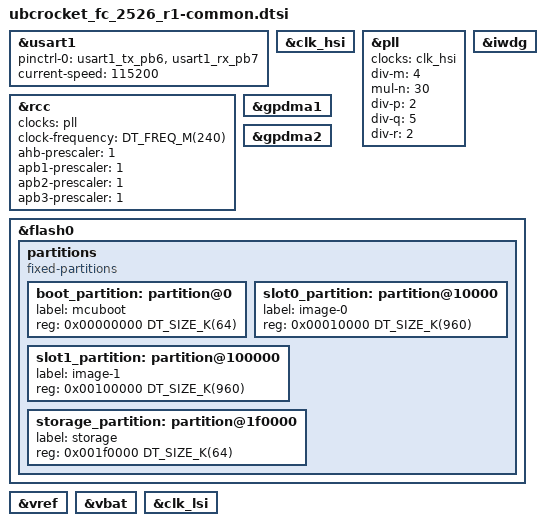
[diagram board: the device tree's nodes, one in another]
/*
 * Copyright (c) 2021 Linaro Limited
 * Copyright (c) 2023 Thomas Stranger
 *
 * SPDX-License-Identifier: Apache-2.0
 */

#include <st/h5/stm32h563Xi.dtsi>
#include <st/h5/stm32h563vitx-pinctrl.dtsi>
#include <zephyr/dt-bindings/input/input-event-codes.h>


&usart1 {
	pinctrl-0 = <&usart1_tx_pb6 &usart1_rx_pb7>;
	pinctrl-names = "default";
	current-speed = <115200>;
	status = "okay";
};


// &clk_hse {
// 	clock-frequency = <DT_FREQ_M(8)>; /* STLink 8MHz clock */
// 	//hse-bypass;
// 	status = "okay";
// };

&clk_hsi {
    status = "okay";
};

// &clk_hsi48 {
// 	status = "okay";
// };

// &clk_lse {
// 	status = "okay";
// };

&pll {
	clocks = <&clk_hsi>;
    div-m = <4>;
    mul-n = <30>;
    div-p = <2>;   // 240 MHz SYSCLK (P)
    div-q = <5>;   // 96 MHz (optional use)
    div-r = <2>;   // 240 MHz (alternate)
    status = "okay";
};

// &i2c1 {
// 	pinctrl-0 = <&i2c1_scl_pb8 &i2c1_sda_pb9>;
// 	pinctrl-names = "default";
// 	status = "disabled";
// };

// &i3c1 {
// 	pinctrl-0 = <&i3c1_scl_pd12 &i3c1_sda_pd13>;
// 	pinctrl-names = "default";
// 	i3c-scl-hz = <12500000>;
// 	status = "okay";
// };

&rcc {
	clocks = <&pll>;
	clock-frequency = <DT_FREQ_M(240)>;
	ahb-prescaler = <1>; //2
	apb1-prescaler = <1>;
	apb2-prescaler = <1>; //2
	apb3-prescaler = <1>;
};

// &lpuart1 {
// 	pinctrl-0 = <&lpuart1_tx_pb6 &lpuart1_rx_pb7>;
// 	pinctrl-names = "default";
// 	current-speed = <115200>;
// 	status = "okay";
// };



// &spi1 {
// 	pinctrl-0 = <&spi1_sck_pa5 &spi1_miso_pb4 &spi1_mosi_pb5>;
// 	pinctrl-names = "default";
// 	cs-gpios = <&gpiod 14 (GPIO_ACTIVE_LOW | GPIO_PULL_UP)>;
// 	status = "okay";
// };

// &timers3 {
// 	st,prescaler = <10000>;
// 	status = "okay";

// 	pwm3: pwm {
// 		status = "okay";
// 		pinctrl-0 = <&tim3_ch3_pb0>;
// 		pinctrl-names = "default";
// 	};
// };

//might need for real-time stuff TODO
// &rtc {
// 	clocks = <&rcc STM32_CLOCK(APB3, 21)>,
// 		 <&rcc STM32_SRC_LSE RTC_SEL(1)>;
// 	status = "okay";
// };

&iwdg {
	status = "okay";
};

&gpdma1 {
	status = "okay";
};

&gpdma2 {
	status = "okay";
};

// &dac1 {
// 	/* outputs only on 2 pins and pa4 is reserved for VBUS_SENSE */
// 	pinctrl-0 = <&dac1_out2_pa5>;  /* Zio D13 (on CN7) */
// 	pinctrl-names = "default";
// 	status = "okay";
// };

// &adc1 {
// 	clocks = <&rcc STM32_CLOCK(AHB2, 10)>,
// 		 <&rcc STM32_SRC_HCLK ADCDAC_SEL(0)>;
// 	pinctrl-0 = <&adc1_inp3_pa6 &adc1_inp15_pa3>; /* Zio A0, Zio D35 */
// 	pinctrl-names = "default";
// 	st,adc-clock-source = "ASYNC";
// 	st,adc-prescaler = <6>;
// 	status = "okay";
// };

// &fdcan1 {
// 	pinctrl-0 = <&fdcan1_rx_pd0 &fdcan1_tx_pd1>;
// 	pinctrl-names = "default";
// 	clocks = <&rcc STM32_CLOCK(APB1_2, 9)>,
// 		 <&rcc STM32_SRC_PLL1_Q FDCAN_SEL(1)>;
// 	clk-divider = <2>;
// 	status = "okay";
// };

&flash0 {
	partitions {
		compatible = "fixed-partitions";
		#address-cells = <1>;
		#size-cells = <1>;

		boot_partition: partition@0 {
			label = "mcuboot";
			reg = <0x00000000 DT_SIZE_K(64)>;
		};

		slot0_partition: partition@10000 {
			label = "image-0";
			reg = <0x00010000 DT_SIZE_K(960)>;
		};

		slot1_partition: partition@100000 {
			label = "image-1";
			reg = <0x00100000 DT_SIZE_K(960)>;
		};

		storage_partition: partition@1f0000 {
			label = "storage";
			reg = <0x001f0000 DT_SIZE_K(64)>;
		};
	};
};

// zephyr_udc0: &usb {
// 	pinctrl-0 = <&usb_dm_pa11 &usb_dp_pa12>;
// 	pinctrl-names = "default";
// 	status = "okay";
// };

&vref {
	status = "okay";
};

&vbat {
	status = "okay";
};

&clk_lsi {
	status = "okay";
};

//TODO may need for low power
// stm32_lp_tick_source: &lptim4 {
// 	clocks = <&rcc STM32_CLOCK(APB3, 13)>,
// 		 <&rcc STM32_SRC_LSI LPTIM4_SEL(4)>;
// 	status = "okay";
// };
